# M0519AE_v1 register map
File version: 1.0
Registers are 32-bit, read-write, reset 0x0 unless marked. A register's access mark holds for its fields unless they carry their own. Offsets are from the block's base; [hi:lo] are bit positions.

## SCB — SCB Register Map
Base 0xE000ED00
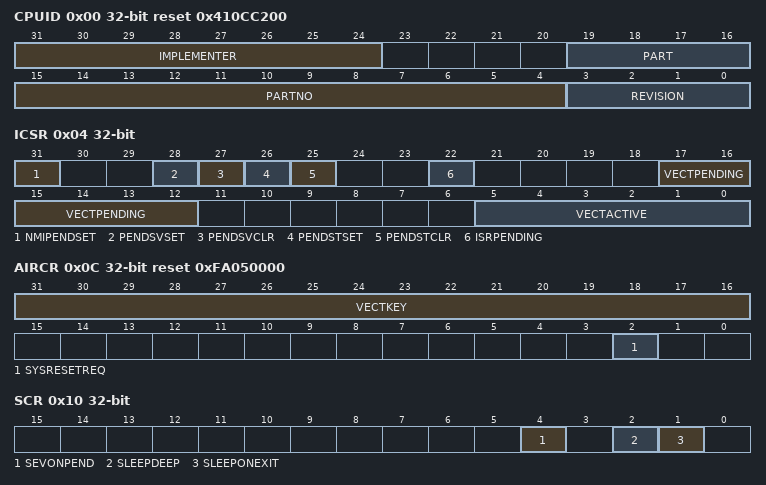
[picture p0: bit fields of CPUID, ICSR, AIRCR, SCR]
0x00 CPUID ro reset 0x410CC200
  [31:24] IMPLEMENTER — Implementer Code Assigned by ARM
  [19:16] PART — Architecture of the Processor. Read as 0xC corresponding to ARMv6-M architecture.
  [15:4] PARTNO — Part Number of the Processor. Reads as 0xC20 corresponding to Cortex-M0
  [3:0] REVISION — Revision Number. Reads as 0x0.
0x04 ICSR — Interrupt Control State Register
  [31] NMIPENDSET — NMI Set-pending Bit. Because NMI is the highest-priority exception, normally the processor enters the NMI exception handler as soon as it detects a write of 1 to this bit. Entering the handler then clears this bit to 0. This means a read of this bit by the NMI exception handler returns 1 only if the NMI signal is reasserted while the processor is executing that handler. Write Operation:
    0=no effect. NMI exception is not pending; 1=changes NMI exception state to pending. NMI exception is pending
  [28] PENDSVSET — PendSV Set-pending Bit. Write Operation: Writing 1 to this bit is the only way to set the PendSV exception state to pending.
    0=no effect. PendSV exception is not pending; 1=changes PendSV exception state to pending. PendSV exception is pending
  [27] PENDSVCLR wo — PendSV Clear-pending Bit (Write Only)
    0=no effect; 1=removes the pending state from the PendSV exception
  [26] PENDSTSET — SysTick Exception Set-pending Bit. Write Operation:
    0=no effect. SysTick exception is not pending; 1=changes SysTick exception state to pending. SysTick exception is pending
  [25] PENDSTCLR wo — SysTick Exception Clear-pending Bit (Write Only)
    0=no effect; 1=removes the pending state from the SysTick exception
  [22] ISRPENDING ro — Interrupt Pending Flag (Read Only). Indicates if an external configurable (NVIC generated) interrupt is pending.
    0=interrupt not pending; 1=interrupt pending
  [17:12] VECTPENDING ro — Vector Pending Indicator (Read Only). This field indicates the exception number of the highest priority pending enabled exception:
    0=no pending exceptions
  [5:0] VECTACTIVE ro — Vector Active Indicator (Read Only). This field contains the active exception number:
    0=Thread mode
0x0C AIRCR reset 0xFA050000 — Application Interrupt and Reset Control Register
  [31:16] VECTKEY wo — Register Key (Write Only). When writing to this register, the VECTORKEY field need to be set to 0x05FA, otherwise the write operation would be ignored. The VECTORKEY filed is used to prevent accidental write to this register from resetting the system or clearing of the exception status.
  [2] SYSRESETREQ wo — System Reset Request (Write Only)
    0=no effect; 1=requests a system level reset
0x10 SCR — System Control Register
  [4] SEVONPEND — Send Event on Pending Bit. When an event or interrupt enters pending state, the event signal wakes up the processor from WFE. If the processor is not waiting for an event, the event is registered and affects next WFE. The processor also wakes up on execution of an SEV instruction or an external event.
    0=Oonly enabled interrupts or events can wake up the processor, disabled interrupts are excluded; 1=Enabled events and all interrupts, including disabled interrupts, can wake-up the processor
  [2] SLEEPDEEP — Deep Sleep Mode Enable Bit. This bit controls whether the processor uses sleep or deep sleep as its low power mode:
    0=Sleep mode; 1=Deep sleep mode
  [1] SLEEPONEXIT — Sleep-on-exit Enable Bit. This bit controls sleep-on-exit when returning from Handler mode to Thread mode: Note: Setting this bit to 1 enables an interrupt driven application to avoid returning to an empty main application.
    0=Do not sleep when returning to Thread mode; 1=Enter Sleep, or Deep Sleep, on return from an ISR to Thread mode
0x1C SHPR2 — System Handler Priority Register 2
  [31:30] PRI_11 — Priority of System Handler 11, SVCall "0" denotes the highest priority and "3" denotes the lowest priority.
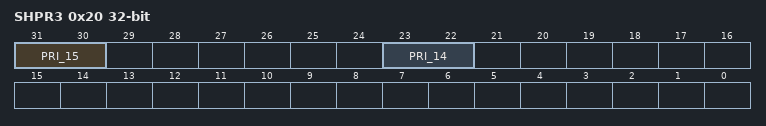
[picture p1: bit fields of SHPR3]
0x20 SHPR3 — System Handler Priority Register 3
  [31:30] PRI_15 — Priority of System Handler 15, SysTick "0" denotes the highest priority and "3" denotes the lowest priority.
  [23:22] PRI_14 — Priority of System Handler 14, PendSV "0" denotes the highest priority and "3" denotes the lowest priority.
